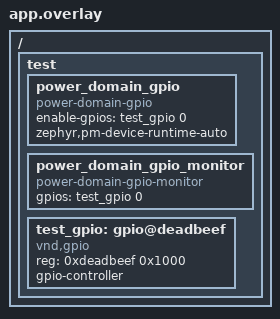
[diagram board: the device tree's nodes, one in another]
/*
 * Copyright (c) 2024 TOKITA Hiroshi
 * SPDX-License-Identifier: Apache-2.0
 */

/ {
	test {
		#address-cells = <1>;
		#size-cells = <1>;

		power_domain_gpio {
			compatible = "power-domain-gpio";
			enable-gpios = <&test_gpio 0 0>;
			#power-domain-cells = <0>;
			zephyr,pm-device-runtime-auto;
		};

		power_domain_gpio_monitor {
			compatible = "power-domain-gpio-monitor";
			gpios = <&test_gpio 0 0>;
			#power-domain-cells = <0>;
			status = "okay";
		};

		test_gpio: gpio@deadbeef {
			compatible = "vnd,gpio";
			reg = <0xdeadbeef 0x1000>;
			gpio-controller;
			#gpio-cells = <0x2>;
			status = "okay";
		};
	};
};
